# NAVSS0_UDMAP_0_ALIAS64K_UDMAP0_CFG_RCHANRT register map
Vendor: Texas Instruments
Peripheral module from a debugger description file (folder J721S2).
Registers are 32-bit, read-write, reset 0x0 unless marked. A register's access mark holds for its fields unless they carry their own. Offsets are as the file gives them; lines under a group give offsets from that group; [hi:lo] are bit positions; {n}, {i} and the like mark numbered series; 'fields as' and 'values as' point back to an identical list; <NAME> marks a mode.

## NAVSS0_UDMAP_0_ALIAS64K_UDMAP0_CFG_RCHANRT
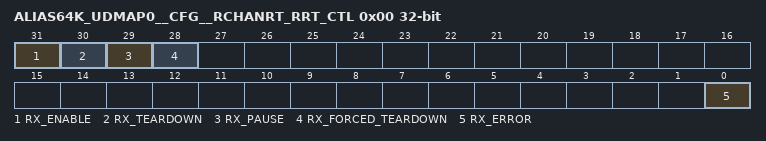
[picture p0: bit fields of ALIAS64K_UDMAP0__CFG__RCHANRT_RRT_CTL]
0x00 ALIAS64K_UDMAP0__CFG__RCHANRT_RRT_CTL access per field — The Rx Channel Realtime Control Register contains real-time control and status information for the Rx DMA channel. The fields in this register can safely be changed while the channel is in operation.
  [31] RX_ENABLE rw — This field enables or disables the channel. Disabling a channel halts operation on the channel after the current block transfer is completed. Disabling a channel in the middle of a packet transfer may result in overflow conditions in the attached application and data loss. When a channel is disabled, the implementation may choose to reset all state for the channel. The pause bit shoudl be asserted instead of clearing enable directly if the intent is to temporarily pause the channel. This field is encoded as follows: 0 = channel is disabled 1 = channel is enabled This field will be cleared by HW after a teardown is requested to indicate tha the channel teardown is complete. If the host is enabling a channel that is just being set up, the host must initialize all of the other channel configuration fields before setting this bit.
  [30] RX_TEARDOWN rw — This field indicates whether or not an Rx teardown operation is complete. This field should be cleared when a channel is initialized. This field will be set after a channel teardown is complete.
  [29] RX_PAUSE rw — Channel pause: Setting this bit will cause the channel to pause processing immediately.
  [28] RX_FORCED_TEARDOWN rw — Channel forced teardown: Setting this bit will cause the channel to stop waiting on trigger events. When this bit is set, the implementation may choose to bypass data transfers and event generation. This bit is a modifier to the normal rx_teardown and is intended to flush the channel to recover any descriptor or TR references which are currently being held by the UDMA even if the trigger source is no longer functioning. Use of this bit is considered a 'catastrophic' condition and it is assumed that SW will need to perform some re-initialization in the system to re-align e vents, data buffers, etc. This bit should be set in addition to the rx_teardown bit in order to cause a forced teardown. This field will remain set after a channel teardown is complete.
  [0] RX_ERROR ro — Channel error: This bit will be set anytime an error has occurred on the channel. This bit is cleared when the channel is disabled and re-enabled.
0x08 ALIAS64K_UDMAP0__CFG__RCHANRT_RRT_SWTRIG access not given — The Software Trigger Register provides a mechanism by which software can directly trigger the channel in a secure way. This register is only used when the rx_chan_type is configured as a Third Party DMA channel. This register has no function when the channel is configured for packet mode transfers. A write to this register will cause an event to be sent to this channel.
  [0] TRIGGER — Trigger: writing this bit with a value of 1 will cause the trigger event to be sent to this channel (access NA/W)
0x40 ALIAS64K_UDMAP0__CFG__RCHANRT_RRT_STATUS0 access not given reset not defined — The Status Register provides a read only view of channel status bits.
0x44 ALIAS64K_UDMAP0__CFG__RCHANRT_RRT_STATUS1 access not given reset not defined — The Status Register provides a read only view of channel status bits.
0x80 ALIAS64K_UDMAP0__CFG__RCHANRT_RRT_STDATA — The State Data Registers contain the current working state of the Rx DMA channel. These registers are provided so that the Host can determine the potential cause of an error or exception condition which was reported by the channel. These registers should not be accessed without reason while the UDMA-P is operating as accesses will cause performance to decrease as these MMRs are just providing a window into the actual state RAM
  [31:0] STATE_INFO — See Rx state mapping table
{0x200+4i} ALIAS64K_UDMAP0__CFG__RCHANRT_RRT_PEER{i} (i=0..15) — This register provides access to the remote peer's realtime register at {0x400+i}.
  [31:0] PEER_DATA — Peer realtime register data (varies by paired peer).
0x400 ALIAS64K_UDMAP0__CFG__RCHANRT_RRT_PCNT access not given — The statistics registers are supplied to give software applications operational progress status for the channel.
  [31:0] PCNT — Current completed packet count for the channel. (access R/WTD)
0x408 ALIAS64K_UDMAP0__CFG__RCHANRT_RRT_BCNT access not given — The statistics registers are supplied to give software applications operational progress status for the channel.
  [31:0] BCNT — Current completed payload byte count for the channel. (access R/WTD)
0x410 ALIAS64K_UDMAP0__CFG__RCHANRT_RRT_SBCNT access not given — The statistics registers are supplied to give software applications operational progress status for the channel.
  [31:0] SBCNT — Current started byte count for the channel. (access R/WTD)
